VERSION "synthetic -- generated by libs/dbc_parser/tests/gen_golden.py"

NS_ :

BS_:

BU_ : ECU

BO_ 768 Multiplexed: 8 ECU
 SG_ MuxIndex M : 0|4@0+ (1,0) [0|15] "" ECU
 SG_ Always : 8|8@0+ (1,0) [0|255] "" ECU
 SG_ Group1 m1 : 16|16@0+ (1,0) [0|65535] "" ECU
 SG_ Group2 m2 : 40|12@1- (1,0) [-2048|2047] "" ECU
 SG_ Group0 m0 : 52|8@1+ (1,0) [0|255] "" ECU
 SG_ Group3 m3 : 3|3@0- (1,0) [-4|3] "" ECU

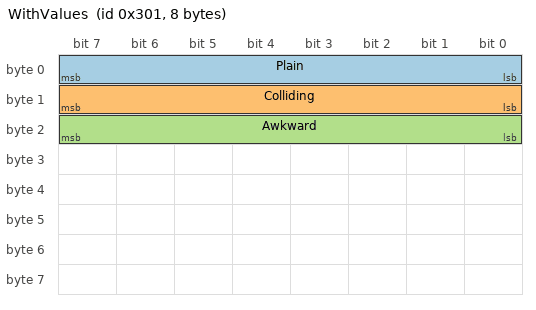
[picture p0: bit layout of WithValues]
BO_ 769 WithValues: 8 ECU
 SG_ Plain : 0|8@1+ (1,0) [0|255] "" ECU
 SG_ Colliding : 8|8@1+ (1,0) [0|255] "" ECU
 SG_ Awkward : 16|8@1+ (1,0) [0|255] "" ECU

BO_ 770 FloatSignals: 8 ECU
 SG_ AsFloat : 0|32@1- (1,0) [-2147483648|2147483647] "" ECU
 SG_ AsInt : 32|32@1+ (1,0) [0|4294967295] "" ECU

BO_ 771 DoubleSignal: 8 ECU
 SG_ AsDouble : 0|64@1- (1,0) [-9223372036854775808|9223372036854775807] "" ECU

BO_ 2566843904 ExtendedId: 8 ECU
 SG_ Payload : 0|32@1+ (1,0) [0|4294967295] "" ECU

VAL_ 769 Plain 0 "Off" 1 "On" 2 "Standby" ;
VAL_ 769 Colliding 0 "Fault-A" 1 "Fault_A" 2 "Fault A" ;
VAL_ 769 Awkward 0 "0 to 100%" 1 "" 2 "class" 3 "---" ;

SIG_VALTYPE_ 770 AsFloat : 1;
SIG_VALTYPE_ 771 AsDouble : 2;

CM_ SG_ 769 Plain "a comment with \"quotes\" and a \\ backslash";
CM_ BO_ 768 "multiplexed message";
